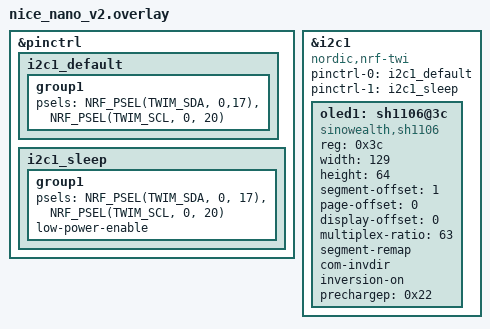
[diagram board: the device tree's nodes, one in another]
&pinctrl {
    i2c1_default: i2c1_default {
        group1 {
            psels = <NRF_PSEL(TWIM_SDA, 0,17)>,
                <NRF_PSEL(TWIM_SCL, 0, 20)>;
        };
    };

    i2c1_sleep: i2c1_sleep {
        group1 {
            psels = <NRF_PSEL(TWIM_SDA, 0, 17)>,
                <NRF_PSEL(TWIM_SCL, 0, 20)>;
            low-power-enable;
        };
    };	
}; 

&i2c1 {
	status = "okay";
	compatible = "nordic,nrf-twi";
    pinctrl-0 = <&i2c1_default>;
    pinctrl-1 = <&i2c1_sleep>;
	oled1: sh1106@3c {
        compatible = "sinowealth,sh1106";
        reg = <0x3c>;
        width = <129>;
        height = <64>;
        segment-offset = <1>;
        page-offset = <0>;
        display-offset = <0>;
        multiplex-ratio = <63>;
        segment-remap;
        com-invdir;
        inversion-on;
        prechargep = <0x22>;
	};
};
